VERSION "DEV DUMMY VERSION OF DBC"

NS_ :

BU_: ExampleNode1 ExampleNode2

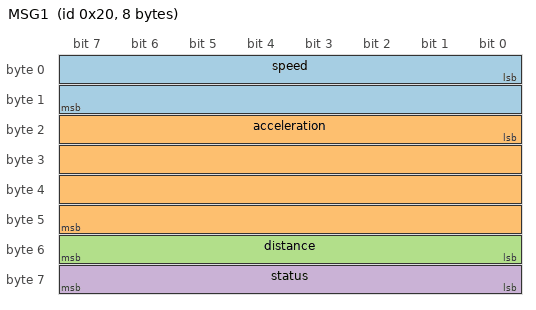
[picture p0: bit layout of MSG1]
BO_ 32 MSG1: 8 ExampleNode1
    SG_ speed : 0|16@1+ (0.001,0) [0|65.535] "m/s" Vector__XXX
    SG_ acceleration : 16|32@1+ (0.000001,0) [0|4294.967295] "m/s^2" Vector__XXX
    SG_ distance : 48|8@1- (1,0) [-128|128] "mm" Vector__XXX
    SG_ status : 56|8@1+ (1,0) [0|255] "-" Vector__XXX

BO_ 255 MSG2: 4 ExampleNode2
    SG_ somesignal : 0|32@1+ (1,0) [0|4294967295] "" Vector__XXX

CM_ BO_ 32 "Example message 1";
CM_ SG_ 32 speed "Example 16 bit signal in message 1";
CM_ SG_ 32 acceleration "Example 32 bit signal in message 1";
CM_ SG_ 32 distance "Example 8 bit signed signal in message 1";
CM_ SG_ 32 status "Example 8 bit unsigned signal in message 1";
CM_ BO_ 255 "Example message 2";
